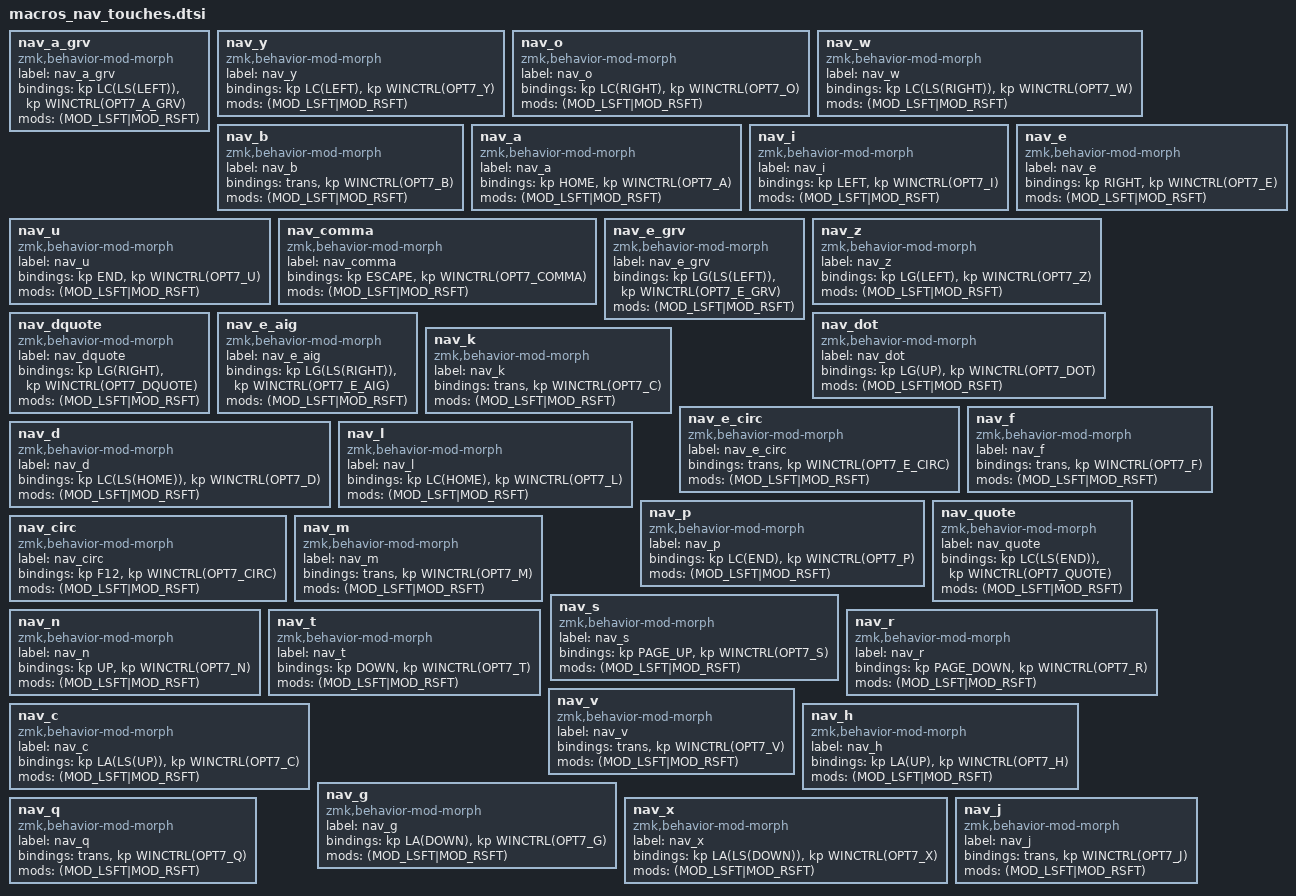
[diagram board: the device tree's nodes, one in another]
// ===========================
// ======= Main gauche =======
// ===========================



// ======= Main gauche, haut =======


// deplacer_mot_gauche
nav_a_grv: nav_a_grv {
	compatible = "zmk,behavior-mod-morph";
	label = "nav_a_grv";
	#binding-cells = <0>;
	bindings = <&kp LC(LS(LEFT))>, <&kp WINCTRL(OPT7_A_GRV)>;
	mods = <(MOD_LSFT|MOD_RSFT)>;
};

// deplacer_selection_mot_gauche
nav_y: nav_y {
	compatible = "zmk,behavior-mod-morph";
	label = "nav_y";
	#binding-cells = <0>;
	bindings = <&kp LC(LEFT)>, <&kp WINCTRL(OPT7_Y)>;
	mods = <(MOD_LSFT|MOD_RSFT)>;
};

// deplacer_selection_mot_droite
nav_o: nav_o {
	compatible = "zmk,behavior-mod-morph";
	label = "nav_o";
	#binding-cells = <0>;
	bindings = <&kp LC(RIGHT)>, <&kp WINCTRL(OPT7_O)>;
	mods = <(MOD_LSFT|MOD_RSFT)>;
};

// deplacer_mot_droite
nav_w: nav_w {
	compatible = "zmk,behavior-mod-morph";
	label = "nav_w";
	#binding-cells = <0>;
	bindings = <&kp LC(LS(RIGHT))>, <&kp WINCTRL(OPT7_W)>;
	mods = <(MOD_LSFT|MOD_RSFT)>;
};

nav_b: nav_b {
	compatible = "zmk,behavior-mod-morph";
	label = "nav_b";
	#binding-cells = <0>;
	bindings = <&trans>, <&kp WINCTRL(OPT7_B)>;
	mods = <(MOD_LSFT|MOD_RSFT)>;
};



// ======= Main gauche, milieu =======


nav_a: nav_a {
	compatible = "zmk,behavior-mod-morph";
	label = "nav_a";
	#binding-cells = <0>;
	bindings = <&kp HOME>, <&kp WINCTRL(OPT7_A)>;
	mods = <(MOD_LSFT|MOD_RSFT)>;
};

nav_i: nav_i {
	compatible = "zmk,behavior-mod-morph";
	label = "nav_i";
	#binding-cells = <0>;
	bindings = <&kp LEFT>, <&kp WINCTRL(OPT7_I)>;
	mods = <(MOD_LSFT|MOD_RSFT)>;
};

nav_e: nav_e {
	compatible = "zmk,behavior-mod-morph";
	label = "nav_e";
	#binding-cells = <0>;
	bindings = <&kp RIGHT>, <&kp WINCTRL(OPT7_E)>;
	mods = <(MOD_LSFT|MOD_RSFT)>;
};

nav_u: nav_u {
	compatible = "zmk,behavior-mod-morph";
	label = "nav_u";
	#binding-cells = <0>;
	bindings = <&kp END>, <&kp WINCTRL(OPT7_U)>;
	mods = <(MOD_LSFT|MOD_RSFT)>;
};

nav_comma: nav_comma {
	compatible = "zmk,behavior-mod-morph";
	label = "nav_comma";
	#binding-cells = <0>;
	bindings = <&kp ESCAPE>, <&kp WINCTRL(OPT7_COMMA)>;
	mods = <(MOD_LSFT|MOD_RSFT)>;
};



// ======= Main gauche, bas =======


// deplacer_ecran_gauche
nav_e_grv: nav_e_grv {
	compatible = "zmk,behavior-mod-morph";
	label = "nav_e_grv";
	#binding-cells = <0>;
	bindings = <&kp LG(LS(LEFT))>, <&kp WINCTRL(OPT7_E_GRV)>;
	mods = <(MOD_LSFT|MOD_RSFT)>;
};

// deplacer_fenetre_gauche
nav_z: nav_z {
	compatible = "zmk,behavior-mod-morph";
	label = "nav_z";
	#binding-cells = <0>;
	bindings = <&kp LG(LEFT)>, <&kp WINCTRL(OPT7_Z)>;
	mods = <(MOD_LSFT|MOD_RSFT)>;
};

// deplacer_fenetre_droite
nav_dquote: nav_dquote {
	compatible = "zmk,behavior-mod-morph";
	label = "nav_dquote";
	#binding-cells = <0>;
	bindings = <&kp LG(RIGHT)>, <&kp WINCTRL(OPT7_DQUOTE)>;
	mods = <(MOD_LSFT|MOD_RSFT)>;
};

// deplacer_ecran_droite
nav_e_aig: nav_e_aig {
	compatible = "zmk,behavior-mod-morph";
	label = "nav_e_aig";
	#binding-cells = <0>;
	bindings = <&kp LG(LS(RIGHT))>, <&kp WINCTRL(OPT7_E_AIG)>;
	mods = <(MOD_LSFT|MOD_RSFT)>;
};

// Fullscreen
nav_dot: nav_dot {
	compatible = "zmk,behavior-mod-morph";
	label = "nav_dot";
	#binding-cells = <0>;
	bindings = <&kp LG(UP)>, <&kp WINCTRL(OPT7_DOT)>;
	mods = <(MOD_LSFT|MOD_RSFT)>;
};



// ======= Main gauche, dernière ligne =======


nav_k: nav_k {
	compatible = "zmk,behavior-mod-morph";
	label = "nav_k";
	#binding-cells = <0>;
	bindings = <&trans>, <&kp WINCTRL(OPT7_C)>;
	mods = <(MOD_LSFT|MOD_RSFT)>;
};

nav_e_circ: nav_e_circ {
	compatible = "zmk,behavior-mod-morph";
	label = "nav_e_circ";
	#binding-cells = <0>;
	bindings = <&trans>, <&kp WINCTRL(OPT7_E_CIRC)>;
	mods = <(MOD_LSFT|MOD_RSFT)>;
};







// ===========================
// ======= Main droite =======
// ===========================



// ======= Main droite, haut =======


nav_f: nav_f {
	compatible = "zmk,behavior-mod-morph";
	label = "nav_f";
	#binding-cells = <0>;
	bindings = <&trans>, <&kp WINCTRL(OPT7_F)>;
	mods = <(MOD_LSFT|MOD_RSFT)>;
};

// copie_debut_doc
nav_d: nav_d {
	compatible = "zmk,behavior-mod-morph";
	label = "nav_d";
	#binding-cells = <0>;
	bindings = <&kp LC(LS(HOME))>, <&kp WINCTRL(OPT7_D)>;
	mods = <(MOD_LSFT|MOD_RSFT)>;
};

// aller_debut_doc
nav_l: nav_l {
	compatible = "zmk,behavior-mod-morph";
	label = "nav_l";
	#binding-cells = <0>;
	bindings = <&kp LC(HOME)>, <&kp WINCTRL(OPT7_L)>;
	mods = <(MOD_LSFT|MOD_RSFT)>;
};

// aller_fin_doc
nav_p: nav_p {
	compatible = "zmk,behavior-mod-morph";
	label = "nav_p";
	#binding-cells = <0>;
	bindings = <&kp LC(END)>, <&kp WINCTRL(OPT7_P)>;
	mods = <(MOD_LSFT|MOD_RSFT)>;
};

// copie_fin_doc
nav_quote: nav_quote {
	compatible = "zmk,behavior-mod-morph";
	label = "nav_quote";
	#binding-cells = <0>;
	bindings = <&kp LC(LS(END))>, <&kp WINCTRL(OPT7_QUOTE)>;
	mods = <(MOD_LSFT|MOD_RSFT)>;
};

nav_circ: nav_circ {
	compatible = "zmk,behavior-mod-morph";
	label = "nav_circ";
	#binding-cells = <0>;
	bindings = <&kp F12>, <&kp WINCTRL(OPT7_CIRC)>;
	mods = <(MOD_LSFT|MOD_RSFT)>;
};



// ======= Main droite, milieu =======


nav_m: nav_m {
	compatible = "zmk,behavior-mod-morph";
	label = "nav_m";
	#binding-cells = <0>;
	bindings = <&trans>, <&kp WINCTRL(OPT7_M)>;
	mods = <(MOD_LSFT|MOD_RSFT)>;
};

nav_s: nav_s {
	compatible = "zmk,behavior-mod-morph";
	label = "nav_s";
	#binding-cells = <0>;
	bindings = <&kp PAGE_UP>, <&kp WINCTRL(OPT7_S)>;
	mods = <(MOD_LSFT|MOD_RSFT)>;
};

nav_n: nav_n {
	compatible = "zmk,behavior-mod-morph";
	label = "nav_n";
	#binding-cells = <0>;
	bindings = <&kp UP>, <&kp WINCTRL(OPT7_N)>;
	mods = <(MOD_LSFT|MOD_RSFT)>;
};

nav_t: nav_t {
	compatible = "zmk,behavior-mod-morph";
	label = "nav_t";
	#binding-cells = <0>;
	bindings = <&kp DOWN>, <&kp WINCTRL(OPT7_T)>;
	mods = <(MOD_LSFT|MOD_RSFT)>;
};

nav_r: nav_r {
	compatible = "zmk,behavior-mod-morph";
	label = "nav_r";
	#binding-cells = <0>;
	bindings = <&kp PAGE_DOWN>, <&kp WINCTRL(OPT7_R)>;
	mods = <(MOD_LSFT|MOD_RSFT)>;
};



// ======= Main droite, bas =======


nav_v: nav_v {
	compatible = "zmk,behavior-mod-morph";
	label = "nav_v";
	#binding-cells = <0>;
	bindings = <&trans>, <&kp WINCTRL(OPT7_V)>;
	mods = <(MOD_LSFT|MOD_RSFT)>;
};

// dupliquer_haut
nav_c: nav_c {
	compatible = "zmk,behavior-mod-morph";
	label = "nav_c";
	#binding-cells = <0>;
	bindings = <&kp LA(LS(UP))>, <&kp WINCTRL(OPT7_C)>;
	mods = <(MOD_LSFT|MOD_RSFT)>;
};

// deplacer_haut
nav_h: nav_h {
	compatible = "zmk,behavior-mod-morph";
	label = "nav_h";
	#binding-cells = <0>;
	bindings = <&kp LA(UP)>, <&kp WINCTRL(OPT7_H)>;
	mods = <(MOD_LSFT|MOD_RSFT)>;
};

// deplacer_bas
nav_g: nav_g {
	compatible = "zmk,behavior-mod-morph";
	label = "nav_g";
	#binding-cells = <0>;
	bindings = <&kp LA(DOWN)>, <&kp WINCTRL(OPT7_G)>;
	mods = <(MOD_LSFT|MOD_RSFT)>;
};

// dupliquer_bas
nav_x: nav_x {
	compatible = "zmk,behavior-mod-morph";
	label = "nav_x";
	#binding-cells = <0>;
	bindings = <&kp LA(LS(DOWN))>, <&kp WINCTRL(OPT7_X)>;
	mods = <(MOD_LSFT|MOD_RSFT)>;
};



// ======= Main droite, dernière ligne =======


nav_q: nav_q {
	compatible = "zmk,behavior-mod-morph";
	label = "nav_q";
	#binding-cells = <0>;
	bindings = <&trans>, <&kp WINCTRL(OPT7_Q)>;
	mods = <(MOD_LSFT|MOD_RSFT)>;
};

nav_j: nav_j {
	compatible = "zmk,behavior-mod-morph";
	label = "nav_j";
	#binding-cells = <0>;
	bindings = <&trans>, <&kp WINCTRL(OPT7_J)>;
	mods = <(MOD_LSFT|MOD_RSFT)>;
};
